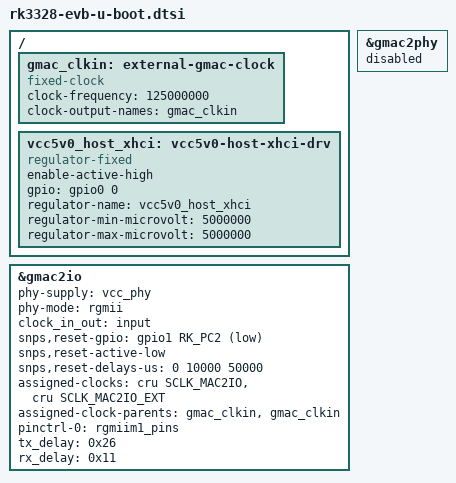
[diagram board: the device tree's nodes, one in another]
// SPDX-License-Identifier: GPL-2.0+
/*
 * (C) Copyright 2016-2019 Rockchip Electronics Co., Ltd
 */

#include "rk3328-u-boot.dtsi"
#include "rk3328-sdram-ddr3-666.dtsi"

/{
	gmac_clkin: external-gmac-clock {
		compatible = "fixed-clock";
		clock-frequency = <125000000>;
		clock-output-names = "gmac_clkin";
		#clock-cells = <0>;
	};

	vcc5v0_host_xhci: vcc5v0-host-xhci-drv {
		compatible = "regulator-fixed";
		enable-active-high;
		gpio = <&gpio0 0 GPIO_ACTIVE_HIGH>;
		regulator-name = "vcc5v0_host_xhci";
		regulator-min-microvolt = <5000000>;
		regulator-max-microvolt = <5000000>;
	};
};

&gmac2io {
	phy-supply = <&vcc_phy>;
	phy-mode = "rgmii";
	clock_in_out = "input";
	snps,reset-gpio = <&gpio1 RK_PC2 GPIO_ACTIVE_LOW>;
	snps,reset-active-low;
	snps,reset-delays-us = <0 10000 50000>;
	assigned-clocks = <&cru SCLK_MAC2IO>, <&cru SCLK_MAC2IO_EXT>;
	assigned-clock-parents = <&gmac_clkin>, <&gmac_clkin>;
	pinctrl-names = "default";
	pinctrl-0 = <&rgmiim1_pins>;
	tx_delay = <0x26>;
	rx_delay = <0x11>;
	status = "okay";
};

&gmac2phy {
	/* Integrated PHY unsupported by U-Boot */
	status = "broken";
};
